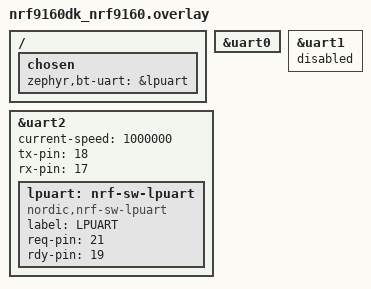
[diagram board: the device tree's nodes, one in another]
/* SPDX-License-Identifier: Apache-2.0 */

/ {
	chosen {
		zephyr,bt-uart=&lpuart;
	};
};

/* Disabling rx pin on console uart to get low power */
&uart0 {
	/delete-property/ rx-pin;
};

&uart1 {
	status = "disabled";
};

&uart2 {
	current-speed = <1000000>;
	status = "okay";
	tx-pin = <18>;
	rx-pin = <17>;
	/delete-property/ rts-pin;
	/delete-property/ cts-pin;

	lpuart: nrf-sw-lpuart {
		compatible = "nordic,nrf-sw-lpuart";
		status = "okay";
		label = "LPUART";
		req-pin = <21>;
		rdy-pin = <19>;
	};
};
